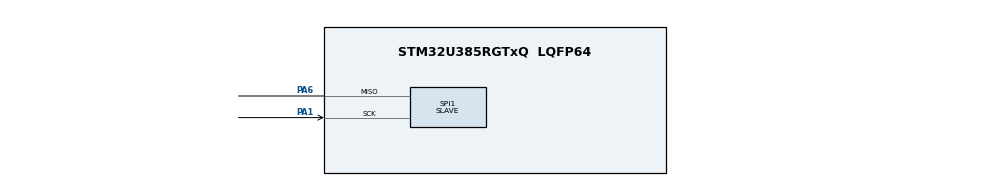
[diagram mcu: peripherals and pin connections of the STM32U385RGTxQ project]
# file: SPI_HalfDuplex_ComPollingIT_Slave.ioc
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CORTEX_M33_NS.userName=CORTEX_M33
Mcu.Family=STM32U3
Mcu.Name=STM32U385RGTxQ
Mcu.Package=LQFP64
NVIC.PriorityGroup=NVIC_PRIORITYGROUP_4
NVIC.SPI1_IRQn=true\:0\:0\:false\:false\:true\:true\:true\:true
PA1.GPIO_Mode=GPIO_MODE_AF_PP
PA1.GPIO_PuPd=GPIO_PULLDOWN
PA1.GPIO_Speed=GPIO_SPEED_FREQ_HIGH
PA1.Mode=Simplex_Bidirectional_Slave
PA1.Signal=SPI1_SCK
PA6.GPIO_PuPd=GPIO_PULLDOWN
PA6.GPIO_Speed=GPIO_SPEED_FREQ_HIGH
PA6.Mode=Simplex_Bidirectional_Slave
PA6.Signal=SPI1_MISO
ProjectManager.HeapSize=0x200
ProjectManager.StackSize=0x400
ProjectManager.TargetToolchain=EWARM V9.20
RCC.ADCFreq_Value=96000000
RCC.AHBFreq_Value=96000000
RCC.APB1Freq_Value=96000000
RCC.APB1TimFreq_Value=96000000
RCC.APB2Freq_Value=96000000
RCC.APB2TimFreq_Value=96000000
RCC.APB3Freq_Value=96000000
RCC.CortexFreq_Value=12000000
RCC.HCLKFreq_Value=96000000
RCC.HSE_VALUE=16000000
RCC.HSI48_VALUE=48000000
RCC.HSI_VALUE=16000000
RCC.LSE_VALUE=32768
RCC.LSIDIV_VALUE=32000
RCC.MSISDIV=RCC_MSI_DIV1
RCC.MSI_VALUE=96000000
RCC.PWR_Regulator_Voltage_Scale=PWR_REGULATOR_VOLTAGE_SCALE1
RCC.SYSCLKFreq_VALUE=96000000
RCC.USBFreq_Value=96000000
SPI1.CLKPhase=SPI_PHASE_1EDGE
SPI1.CLKPolarity=SPI_POLARITY_LOW
SPI1.CRCCalculation=SPI_CRCCALCULATION_DISABLE
SPI1.DataSize=SPI_DATASIZE_8BIT
SPI1.Direction=SPI_DIRECTION_1LINE
SPI1.FirstBit=SPI_FIRSTBIT_MSB
SPI1.Mode=SPI_MODE_SLAVE
SPI1.NSS=SPI_NSS_SOFT
SPI1.TIMode=SPI_TIMODE_DISABLE
SPI1.VirtualType=VM_SLAVE
VP_ICACHE_VS_ICACHE.Mode=DirectMappedCache
VP_PWR_VS_DBSignals.Mode=DisableDeadBatterySignals
VP_PWR_VS_LPOM.Mode=PowerOptimisation
VP_PWR_VS_SECSignals.Mode=Security/Privilege
board=custom

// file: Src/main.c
/* USER CODE BEGIN Header */
/**
  ******************************************************************************
  * @file    SPI/SPI_HalfDuplex_ComPollingIT_Slave/Src/main.c
  * @author  MCD Application Team
  * @brief   This sample code shows how to use STM32U3xx SPI HAL API to transmit
  *          and receive a data buffer with a communication process based on
  *          Interrupt transfer.
  *          The communication is done using 2 Boards.
  ******************************************************************************
  * @attention
  *
  * Copyright (c) 2024 STMicroelectronics.
  * All rights reserved.
  *
  * This software is licensed under terms that can be found in the LICENSE file
  * in the root directory of this software component.
  * If no LICENSE file comes with this software, it is provided AS-IS.
  *
  ******************************************************************************
  */
/* USER CODE END Header */
#include "main.h"

/* USER CODE BEGIN PD */
enum {
	TRANSFER_WAIT,
	TRANSFER_COMPLETE,
	TRANSFER_ERROR
};
/* USER CODE END PD */

SPI_HandleTypeDef hspi1;

/* USER CODE BEGIN PV */
/* Buffer used for transmission */
uint8_t aTxBuffer[] = "**** SPI - Two Boards communication based on Polling (LL driver) for Master Board and Interrupt (HAL Driver) for Slave Board ****";

/* Buffer used for reception */
uint8_t aRxBuffer[BUFFERSIZE];

/* transfer state */
__IO uint32_t wTransferState = TRANSFER_WAIT;
/* USER CODE END PV */

void SystemClock_Config(void);
static void MX_GPIO_Init(void);
static void MX_SPI1_Init(void);
static void MX_ICACHE_Init(void);
/* USER CODE BEGIN PFP */
static uint16_t Buffercmp(uint8_t *pBuffer1, uint8_t *pBuffer2, uint16_t BufferLength);

/* USER CODE END PFP */

int main(void)
{

  /* USER CODE BEGIN 1 */

  /* STM32U3xx HAL library initialization:
       - Configure the Flash prefetch
       - Configure the Systick to generate an interrupt each 1 msec
       - Set NVIC Group Priority to 3
       - Low Level Initialization
     */
  /* USER CODE END 1 */

  /* MCU Configuration--------------------------------------------------------*/

  /* Reset of all peripherals, Initializes the Flash interface and the Systick. */
  HAL_Init();

  /* Configure the system clock */
  SystemClock_Config();

  /* Initialize all configured peripherals */
  MX_GPIO_Init();
  MX_SPI1_Init();
  MX_ICACHE_Init();
  /* USER CODE BEGIN 2 */

  /* Configure LED2 */
  BSP_LED_Init(LD2);

  /*##-1- Start the Half Duplex Communication process ########################*/
  /* While the SPI in Receive process, user can receive data through "aRxBuffer" */
  if(HAL_SPI_Receive_IT(&hspi1, (uint8_t *)aRxBuffer, BUFFERSIZE) != HAL_OK)
  {
    /* Transfer error in transmission process */
    Error_Handler();
  }

  /*##-2- Wait for the end of the transfer ###################################*/
  /*  Before starting a new communication transfer, you must wait the callback call
      to get the transfer complete confirmation or an error detection.
      For simplicity reasons, this example is just waiting till the end of the
      transfer, but application may perform other tasks while transfer operation
      is ongoing. */
  while (wTransferState == TRANSFER_WAIT)
  {
  }

  switch(wTransferState)
  {
    case TRANSFER_COMPLETE :
      /*##-4- Compare the sent and received buffers ##############################*/
      if(Buffercmp((uint8_t*)aTxBuffer, (uint8_t*)aRxBuffer, BUFFERSIZE))
      {
        /* Processing Error */
        Error_Handler();
      }
      else
      {
        BSP_LED_On(LD2);
      }
    break;
    default :
      Error_Handler();
    break;
  }

  /* USER CODE END 2 */

  /* Infinite loop */
  while (1)
  {

  }
}

void SystemClock_Config(void)
{
  RCC_OscInitTypeDef RCC_OscInitStruct = {0};
  RCC_ClkInitTypeDef RCC_ClkInitStruct = {0};

  /** Enable Epod Booster
  */
  if (HAL_RCCEx_EpodBoosterClkConfig(RCC_EPODBOOSTER_SOURCE_MSIS, RCC_EPODBOOSTER_DIV1) != HAL_OK)
  {
    Error_Handler();
  }

  if (HAL_PWREx_EnableEpodBooster() != HAL_OK)
  {
    Error_Handler();
  }

  /** Configure the main internal regulator output voltage
  */
  if (HAL_PWREx_ControlVoltageScaling(PWR_REGULATOR_VOLTAGE_SCALE1) != HAL_OK)
  {
    Error_Handler();
  }

  /** Set Flash latency before increasing MSIS
  */
  __HAL_FLASH_SET_LATENCY(FLASH_LATENCY_2);

  /** Initializes the CPU, AHB and APB buses clocks
  */
  RCC_OscInitStruct.OscillatorType = RCC_OSCILLATORTYPE_MSIS;
  RCC_OscInitStruct.MSISState = RCC_MSI_ON;
  RCC_OscInitStruct.MSISSource = RCC_MSI_RC0;
  RCC_OscInitStruct.MSISDiv = RCC_MSI_DIV1;
  if (HAL_RCC_OscConfig(&RCC_OscInitStruct) != HAL_OK)
  {
    Error_Handler();
  }

  /** Initializes the CPU, AHB and APB buses clocks
  */
  RCC_ClkInitStruct.ClockType = RCC_CLOCKTYPE_HCLK|RCC_CLOCKTYPE_SYSCLK
                              |RCC_CLOCKTYPE_PCLK1|RCC_CLOCKTYPE_PCLK2
                              |RCC_CLOCKTYPE_PCLK3;
  RCC_ClkInitStruct.SYSCLKSource = RCC_SYSCLKSOURCE_MSIS;
  RCC_ClkInitStruct.AHBCLKDivider = RCC_SYSCLK_DIV1;
  RCC_ClkInitStruct.APB1CLKDivider = RCC_HCLK_DIV1;
  RCC_ClkInitStruct.APB2CLKDivider = RCC_HCLK_DIV1;
  RCC_ClkInitStruct.APB3CLKDivider = RCC_HCLK_DIV1;

  if (HAL_RCC_ClockConfig(&RCC_ClkInitStruct, FLASH_LATENCY_2) != HAL_OK)
  {
    Error_Handler();
  }
}

static void MX_ICACHE_Init(void)
{

  /** Enable instruction cache in 1-way (direct mapped cache)
  */
  if (HAL_ICACHE_ConfigAssociativityMode(ICACHE_1WAY) != HAL_OK)
  {
    Error_Handler();
  }
  if (HAL_ICACHE_Enable() != HAL_OK)
  {
    Error_Handler();
  }

}

static void MX_SPI1_Init(void)
{

  SPI_AutonomousModeConfTypeDef HAL_SPI_AutonomousMode_Cfg_Struct = {0};

  /* SPI1 parameter configuration*/
  hspi1.Instance = SPI1;
  hspi1.Init.Mode = SPI_MODE_SLAVE;
  hspi1.Init.Direction = SPI_DIRECTION_1LINE;
  hspi1.Init.DataSize = SPI_DATASIZE_8BIT;
  hspi1.Init.CLKPolarity = SPI_POLARITY_LOW;
  hspi1.Init.CLKPhase = SPI_PHASE_1EDGE;
  hspi1.Init.NSS = SPI_NSS_SOFT;
  hspi1.Init.FirstBit = SPI_FIRSTBIT_MSB;
  hspi1.Init.TIMode = SPI_TIMODE_DISABLE;
  hspi1.Init.CRCCalculation = SPI_CRCCALCULATION_DISABLE;
  hspi1.Init.CRCPolynomial = 0x7;
  hspi1.Init.NSSPMode = SPI_NSS_PULSE_DISABLE;
  hspi1.Init.NSSPolarity = SPI_NSS_POLARITY_LOW;
  hspi1.Init.FifoThreshold = SPI_FIFO_THRESHOLD_01DATA;
  hspi1.Init.MasterSSIdleness = SPI_MASTER_SS_IDLENESS_00CYCLE;
  hspi1.Init.MasterInterDataIdleness = SPI_MASTER_INTERDATA_IDLENESS_00CYCLE;
  hspi1.Init.MasterReceiverAutoSusp = SPI_MASTER_RX_AUTOSUSP_DISABLE;
  hspi1.Init.MasterKeepIOState = SPI_MASTER_KEEP_IO_STATE_DISABLE;
  hspi1.Init.IOSwap = SPI_IO_SWAP_DISABLE;
  hspi1.Init.ReadyMasterManagement = SPI_RDY_MASTER_MANAGEMENT_INTERNALLY;
  hspi1.Init.ReadyPolarity = SPI_RDY_POLARITY_HIGH;
  if (HAL_SPI_Init(&hspi1) != HAL_OK)
  {
    Error_Handler();
  }
  HAL_SPI_AutonomousMode_Cfg_Struct.TriggerState = SPI_AUTO_MODE_DISABLE;
  HAL_SPI_AutonomousMode_Cfg_Struct.TriggerSelection = SPI_GRP1_GPDMA_CH0_TCF_TRG;
  HAL_SPI_AutonomousMode_Cfg_Struct.TriggerPolarity = SPI_TRIG_POLARITY_RISING;
  if (HAL_SPIEx_SetConfigAutonomousMode(&hspi1, &HAL_SPI_AutonomousMode_Cfg_Struct) != HAL_OK)
  {
    Error_Handler();
  }

}

static void MX_GPIO_Init(void)
{

  /* GPIO Ports Clock Enable */
  __HAL_RCC_GPIOA_CLK_ENABLE();

}

/* USER CODE BEGIN 4 */
/**
  * @brief  Compares two buffers.
  * @param  pBuffer1, pBuffer2: buffers to be compared.
  * @param  BufferLength: buffer's length
  * @retval 0  : pBuffer1 identical to pBuffer2
  *         >0 : pBuffer1 differs from pBuffer2
  */
static uint16_t Buffercmp(uint8_t* pBuffer1, uint8_t* pBuffer2, uint16_t BufferLength)
{
  while (BufferLength--)
  {
    if((*pBuffer1) != *pBuffer2)
    {
      return BufferLength;
    }
    pBuffer1++;
    pBuffer2++;
  }

  return 0;
}

/******************************************************************************/
/*   USER IRQ HANDLER TREATMENT                                               */
/******************************************************************************/

/**
  * @brief  Tx Transfer completed callback.
  * @param  hspi: SPI handle
  * @note   This example shows a simple way to report end of Interrupt Tx transfer, and
  *         you can add your own implementation.
  * @retval None
  */
void HAL_SPI_RxCpltCallback(SPI_HandleTypeDef *hspi)
{
  /* Transfer in reception process is complete */
  wTransferState = TRANSFER_COMPLETE;
}

/**
  * @brief  SPI error callbacks.
  * @param  hspi: SPI handle
  * @note   This example shows a simple way to report transfer error, and you can
  *         add your own implementation.
  * @retval None
  */
void HAL_SPI_ErrorCallback(SPI_HandleTypeDef *hspi)
{
  wTransferState = TRANSFER_ERROR;
}
/* USER CODE END 4 */

void Error_Handler(void)
{
  /* USER CODE BEGIN Error_Handler_Debug */
  /* User can add his own implementation to report the HAL error return state */
  while(1)
  {
    /* Toggle LD2 for error */
    BSP_LED_Toggle(LD2);
    HAL_Delay(1000);
  }
  /* USER CODE END Error_Handler_Debug */
}
